AUTOSAR XML (schema 3.1.2)
package /Components/SWC_AdvSpT
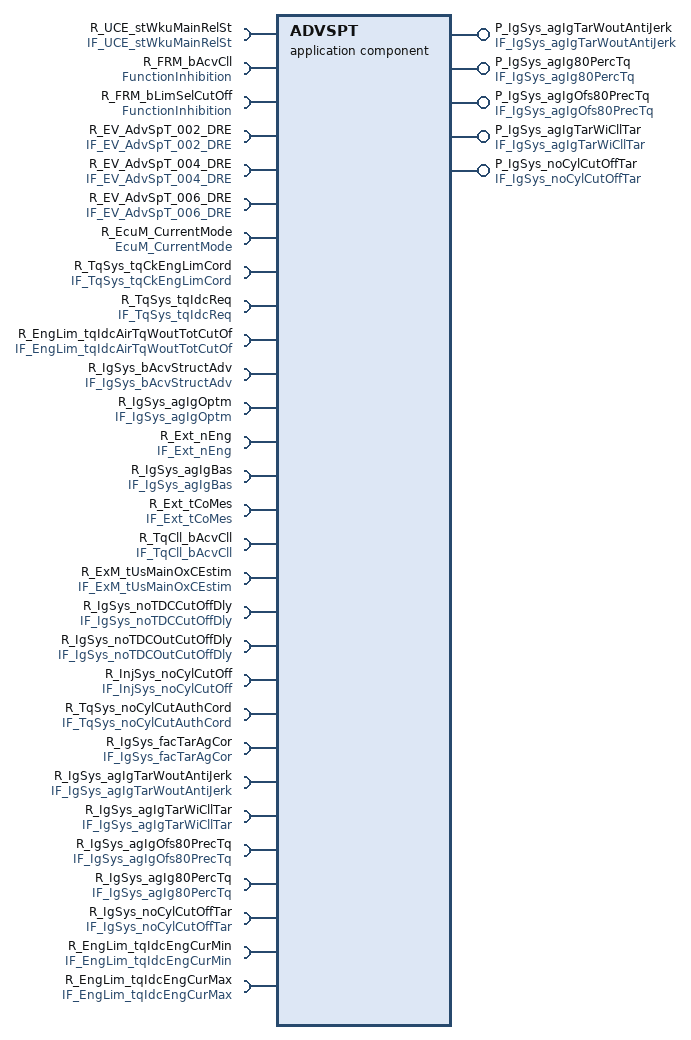
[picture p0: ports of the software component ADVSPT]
  application software component type ADVSPT  # AdvSpT
    require port R_UCE_stWkuMainRelSt: required-interface=IF_UCE_stWkuMainRelSt
    require port R_FRM_bAcvCll: required-interface=FunctionInhibition
    require port R_FRM_bLimSelCutOff: required-interface=FunctionInhibition
    5 x provide port:
      P_IgSys_agIgTarWoutAntiJerk: unqueued-sender-com-spec{data-element=IgSys_agIgTarWoutAntiJerk, can-invalidate=false, init-value=UInt8InitValue}, provided-interface=IF_IgSys_agIgTarWoutAntiJerk
      P_IgSys_agIg80PercTq: unqueued-sender-com-spec{data-element=IgSys_agIg80PercTq, can-invalidate=false, init-value=UInt8InitValue1}, provided-interface=IF_IgSys_agIg80PercTq
      P_IgSys_agIgOfs80PrecTq: unqueued-sender-com-spec{data-element=IgSys_agIgOfs80PrecTq, can-invalidate=false, init-value=UInt8InitValue3}, provided-interface=IF_IgSys_agIgOfs80PrecTq
      P_IgSys_agIgTarWiCllTar: unqueued-sender-com-spec{data-element=IgSys_agIgTarWiCllTar, can-invalidate=false, init-value=ConstantValue}, provided-interface=IF_IgSys_agIgTarWiCllTar
      P_IgSys_noCylCutOffTar: unqueued-sender-com-spec{data-element=IgSys_noCylCutOffTar, can-invalidate=false, init-value=UInt8InitValue5}, provided-interface=IF_IgSys_noCylCutOffTar
    26 x require port:
      R_EV_AdvSpT_002_DRE: unqueued-receiver-com-spec{data-element=EV_AdvSpT_002_DRE, init-value=UInt8InitValue7, resync-time=0}, required-interface=IF_EV_AdvSpT_002_DRE
      R_EV_AdvSpT_004_DRE: unqueued-receiver-com-spec{data-element=EV_AdvSpT_004_DRE, init-value=UInt8InitValue9, resync-time=0}, required-interface=IF_EV_AdvSpT_004_DRE
      R_EV_AdvSpT_006_DRE: unqueued-receiver-com-spec{data-element=EV_AdvSpT_006_DRE, init-value=UInt8InitValue11, resync-time=0}, required-interface=IF_EV_AdvSpT_006_DRE
      R_EcuM_CurrentMode: required-interface=EcuM_CurrentMode
      R_TqSys_tqCkEngLimCord: unqueued-receiver-com-spec{data-element=TqSys_tqCkEngLimCord, init-value=SInt16InitValue, resync-time=0}, required-interface=IF_TqSys_tqCkEngLimCord
      R_TqSys_tqIdcReq: unqueued-receiver-com-spec{data-element=TqSys_tqIdcReq, init-value=SInt16InitValue13, resync-time=0}, required-interface=IF_TqSys_tqIdcReq
      R_EngLim_tqIdcAirTqWoutTotCutOf: unqueued-receiver-com-spec{data-element=EngLim_tqIdcAirTqWoutTotCutOf, init-value=SInt16InitValue15, resync-time=0}, required-interface=IF_EngLim_tqIdcAirTqWoutTotCutOf
      R_IgSys_bAcvStructAdv: unqueued-receiver-com-spec{data-element=IgSys_bAcvStructAdv, init-value=ConstantValue17, resync-time=0}, required-interface=IF_IgSys_bAcvStructAdv
      R_IgSys_agIgOptm: unqueued-receiver-com-spec{data-element=IgSys_agIgOptm, init-value=ConstantValue19, resync-time=0}, required-interface=IF_IgSys_agIgOptm
      R_Ext_nEng: unqueued-receiver-com-spec{data-element=Ext_nEng, init-value=ConstantValue21, resync-time=0}, required-interface=IF_Ext_nEng
      R_IgSys_agIgBas: unqueued-receiver-com-spec{data-element=IgSys_agIgBas, init-value=ConstantValue23, resync-time=0}, required-interface=IF_IgSys_agIgBas
      R_Ext_tCoMes: unqueued-receiver-com-spec{data-element=Ext_tCoMes, init-value=ConstantValue25, resync-time=0}, required-interface=IF_Ext_tCoMes
      R_TqCll_bAcvCll: unqueued-receiver-com-spec{data-element=TqCll_bAcvCll, init-value=BooleanInitValue, resync-time=0}, required-interface=IF_TqCll_bAcvCll
      R_ExM_tUsMainOxCEstim: unqueued-receiver-com-spec{data-element=ExM_tUsMainOxCEstim, init-value=UInt16InitValue, resync-time=0}, required-interface=IF_ExM_tUsMainOxCEstim
      R_IgSys_noTDCCutOffDly: unqueued-receiver-com-spec{data-element=IgSys_noTDCCutOffDly, init-value=UInt8InitValue27, resync-time=0}, required-interface=IF_IgSys_noTDCCutOffDly
      R_IgSys_noTDCOutCutOffDly: unqueued-receiver-com-spec{data-element=IgSys_noTDCOutCutOffDly, init-value=UInt8InitValue29, resync-time=0}, required-interface=IF_IgSys_noTDCOutCutOffDly
      R_InjSys_noCylCutOff: unqueued-receiver-com-spec{data-element=InjSys_noCylCutOff, init-value=ConstantValue31, resync-time=0}, required-interface=IF_InjSys_noCylCutOff
      R_TqSys_noCylCutAuthCord: unqueued-receiver-com-spec{data-element=TqSys_noCylCutAuthCord, init-value=UInt8InitValue33, resync-time=0}, required-interface=IF_TqSys_noCylCutAuthCord
      R_IgSys_facTarAgCor: unqueued-receiver-com-spec{data-element=IgSys_facTarAgCor, init-value=UInt16InitValue35, resync-time=0}, required-interface=IF_IgSys_facTarAgCor
      R_IgSys_agIgTarWoutAntiJerk: unqueued-receiver-com-spec{data-element=IgSys_agIgTarWoutAntiJerk, init-value=UInt8InitValue, resync-time=0}, required-interface=IF_IgSys_agIgTarWoutAntiJerk
      R_IgSys_agIgTarWiCllTar: unqueued-receiver-com-spec{data-element=IgSys_agIgTarWiCllTar, init-value=ConstantValue, resync-time=0}, required-interface=IF_IgSys_agIgTarWiCllTar
      R_IgSys_agIgOfs80PrecTq: unqueued-receiver-com-spec{data-element=IgSys_agIgOfs80PrecTq, init-value=UInt8InitValue37, resync-time=0}, required-interface=IF_IgSys_agIgOfs80PrecTq
      R_IgSys_agIg80PercTq: unqueued-receiver-com-spec{data-element=IgSys_agIg80PercTq, init-value=UInt8InitValue39, resync-time=0}, required-interface=IF_IgSys_agIg80PercTq
      R_IgSys_noCylCutOffTar: unqueued-receiver-com-spec{data-element=IgSys_noCylCutOffTar, init-value=UInt8InitValue41, resync-time=0}, required-interface=IF_IgSys_noCylCutOffTar
      R_EngLim_tqIdcEngCurMin: unqueued-receiver-com-spec{data-element=EngLim_tqIdcEngCurMin, init-value=SInt16InitValue43, resync-time=0}, required-interface=IF_EngLim_tqIdcEngCurMin
      R_EngLim_tqIdcEngCurMax: unqueued-receiver-com-spec{data-element=EngLim_tqIdcEngCurMax, init-value=SInt16InitValue45, resync-time=0}, required-interface=IF_EngLim_tqIdcEngCurMax
  30 x constant specification:
    BooleanInitValue
      value:
        boolean literal BooleanInitValue: type=DT_TqCll_bAcvCll, value=false
    ConstantValue
      value:
        integer literal ConstantValue: type=DT_IgSys_agIgTarWiCllTar, value=150
    ConstantValue17
      value:
        boolean literal ConstantValue17: type=DT_IgSys_bAcvStructAdv, value=false
    ConstantValue19
      value:
        integer literal ConstantValue19: type=DT_IgSys_agIgOptm, value=149
    ConstantValue21
      value:
        integer literal ConstantValue21: type=DT_Ext_nEng, value=0
    ConstantValue23
      value:
        integer literal ConstantValue23: type=DT_IgSys_agIgBas, value=149
    ConstantValue25
      value:
        integer literal ConstantValue25: type=DT_Ext_tCoMes, value=20
    ConstantValue31
      value:
        integer literal ConstantValue31: type=DT_InjSys_noCylCutOff, value=0
    InitValue_UInt16_0
      value:
        integer literal InitValue_UInt16_0: type=DT_IgSys_rTarEfcWoutAntiJerk_irv, value=0
    InitValue_UInt16_047
      value:
        integer literal InitValue_UInt16_047: type=DT_IgSys_rTarEfc_irv, value=0
    SInt16InitValue
      value:
        integer literal SInt16InitValue: type=DT_TqSys_tqCkEngLimCord, value=0
    SInt16InitValue13
      value:
        integer literal SInt16InitValue13: type=DT_TqSys_tqIdcReq, value=0
    SInt16InitValue15
      value:
        integer literal SInt16InitValue15: type=DT_EngLim_tqIdcAirTqWoutTotCutOf, value=0
    SInt16InitValue43
      value:
        integer literal SInt16InitValue43: type=DT_EngLim_tqIdcEngCurMin, value=0
    SInt16InitValue45
      value:
        integer literal SInt16InitValue45: type=DT_EngLim_tqIdcEngCurMax, value=32000
    UInt16InitValue
      value:
        integer literal UInt16InitValue: type=DT_ExM_tUsMainOxCEstim, value=0
    UInt16InitValue35
      value:
        integer literal UInt16InitValue35: type=DT_IgSys_facTarAgCor, value=256
    UInt8InitValue
      value:
        integer literal UInt8InitValue: type=DT_IgSys_agIgTarWoutAntiJerk, value=150
    UInt8InitValue1
      value:
        integer literal UInt8InitValue1: type=DT_IgSys_agIg80PercTq, value=96
    UInt8InitValue11
      value:
        integer literal UInt8InitValue11: type=DT_EV_AdvSpT_006_DRE, value=0
    UInt8InitValue27
      value:
        integer literal UInt8InitValue27: type=DT_IgSys_noTDCCutOffDly, value=0
    UInt8InitValue29
      value:
        integer literal UInt8InitValue29: type=DT_IgSys_noTDCOutCutOffDly, value=0
    UInt8InitValue3
      value:
        integer literal UInt8InitValue3: type=DT_IgSys_agIgOfs80PrecTq, value=96
    UInt8InitValue33
      value:
        integer literal UInt8InitValue33: type=DT_TqSys_noCylCutAuthCord, value=0
    UInt8InitValue37
      value:
        integer literal UInt8InitValue37: type=DT_IgSys_agIgOfs80PrecTq, value=96
    UInt8InitValue39
      value:
        integer literal UInt8InitValue39: type=DT_IgSys_agIg80PercTq, value=96
    UInt8InitValue41
      value:
        integer literal UInt8InitValue41: type=DT_IgSys_noCylCutOffTar, value=0
    UInt8InitValue5
      value:
        integer literal UInt8InitValue5: type=DT_IgSys_noCylCutOffTar, value=0
    UInt8InitValue7
      value:
        integer literal UInt8InitValue7: type=DT_EV_AdvSpT_002_DRE, value=0
    UInt8InitValue9
      value:
        integer literal UInt8InitValue9: type=DT_EV_AdvSpT_004_DRE, value=0
  internal behavior IB_AdvSpT: component=ADVSPT
    data received event EV_AdvSpT_004_DRE: mode-dependency=dependent-on-mode=[R_UCE_stWkuMainRelSt.RCD_stWkuMainRelSt.PreMainWakeUp, R_UCE_stWkuMainRelSt.RCD_stWkuMainRelSt.PostMainWakeUp, R_UCE_stWkuMainRelSt.RCD_stWkuMainRelSt.Invalid], start-on-event=RE_AdvSpT_004_DRE, data=R_EV_AdvSpT_004_DRE.EV_AdvSpT_004_DRE
    data received event EV_AdvSpT_006_DRE: mode-dependency=dependent-on-mode=[R_UCE_stWkuMainRelSt.RCD_stWkuMainRelSt.PreMainWakeUp, R_UCE_stWkuMainRelSt.RCD_stWkuMainRelSt.PostMainWakeUp, R_UCE_stWkuMainRelSt.RCD_stWkuMainRelSt.Invalid], start-on-event=RE_AdvSpT_006_DRE, data=R_EV_AdvSpT_006_DRE.EV_AdvSpT_006_DRE
    mode switch event EV_AdvSpT_005_MSE: start-on-event=RE_AdvSpT_005_MSE, activation=ENTRY, mode=R_EcuM_CurrentMode.currentMode.RUN
    mode switch event EV_AdvSpT_003_MSE: start-on-event=RE_AdvSpT_003_MSE, activation=ENTRY, mode=R_EcuM_CurrentMode.currentMode.RUN
    mode switch event EV_AdvSpT_001_MSE: start-on-event=RE_AdvSpT_001_MSE, activation=ENTRY, mode=R_EcuM_CurrentMode.currentMode.RUN
    data received event EV_AdvSpT_002_DRE: mode-dependency=dependent-on-mode=[R_UCE_stWkuMainRelSt.RCD_stWkuMainRelSt.PreMainWakeUp, R_UCE_stWkuMainRelSt.RCD_stWkuMainRelSt.PostMainWakeUp, R_UCE_stWkuMainRelSt.RCD_stWkuMainRelSt.Invalid], start-on-event=RE_AdvSpT_002_DRE, data=R_EV_AdvSpT_002_DRE.EV_AdvSpT_002_DRE
    inter runnable variable IgSys_rTarEfc_irv: sw-calibration-access=READ-WRITE, type=DT_IgSys_rTarEfc_irv, communication-approach=EXPLICIT, init-value=InitValue_UInt16_047
    inter runnable variable IgSys_rTarEfcWoutAntiJerk_irv: sw-calibration-access=READ-WRITE, type=DT_IgSys_rTarEfcWoutAntiJerk_irv, communication-approach=EXPLICIT, init-value=InitValue_UInt16_0
    6 x runnable:
      RE_AdvSpT_001_MSE: written-variable=[IgSys_rTarEfc_irv, IgSys_rTarEfcWoutAntiJerk_irv]
      RE_AdvSpT_002_DRE: read-variable=[IgSys_rTarEfc_irv, IgSys_rTarEfcWoutAntiJerk_irv], written-variable=[IgSys_rTarEfc_irv, IgSys_rTarEfcWoutAntiJerk_irv]
        5 x data receive point:
          dr_EV_AdvSpT_002_DRE: data-element=R_EV_AdvSpT_002_DRE.EV_AdvSpT_002_DRE
          dr_IgSys_bAcvStructAdv: data-element=R_IgSys_bAcvStructAdv.IgSys_bAcvStructAdv
          dr_TqSys_tqCkEngLimCord: data-element=R_TqSys_tqCkEngLimCord.TqSys_tqCkEngLimCord
          dr_TqSys_tqIdcReq: data-element=R_TqSys_tqIdcReq.TqSys_tqIdcReq
          dr_EngLim_tqIdcAirTqWoutTotCutOf: data-element=R_EngLim_tqIdcAirTqWoutTotCutOf.EngLim_tqIdcAirTqWoutTotCutOf
      RE_AdvSpT_003_MSE
        data send point ds_IgSys_noCylCutOffTar: data-element=P_IgSys_noCylCutOffTar.IgSys_noCylCutOffTar
      RE_AdvSpT_006_DRE: read-variable=[IgSys_rTarEfcWoutAntiJerk_irv, IgSys_rTarEfc_irv]
        10 x data receive point:
          dr_IgSys_bAcvStructAdv: data-element=R_IgSys_bAcvStructAdv.IgSys_bAcvStructAdv
          dr_IgSys_agIg80PercTq: data-element=R_IgSys_agIg80PercTq.IgSys_agIg80PercTq
          dr_IgSys_agIgBas: data-element=R_IgSys_agIgBas.IgSys_agIgBas
          dr_IgSys_agIgOptm: data-element=R_IgSys_agIgOptm.IgSys_agIgOptm
          dr_TqCll_bAcvCll: data-element=R_TqCll_bAcvCll.TqCll_bAcvCll
          dr_IgSys_agIgOfs80PrecTq: data-element=R_IgSys_agIgOfs80PrecTq.IgSys_agIgOfs80PrecTq
          dr_IgSys_facTarAgCor: data-element=R_IgSys_facTarAgCor.IgSys_facTarAgCor
          dr_EV_AdvSpT_006_DRE: data-element=R_EV_AdvSpT_006_DRE.EV_AdvSpT_006_DRE
          dr_IgSys_agIgTarWoutAntiJerk: data-element=R_IgSys_agIgTarWoutAntiJerk.IgSys_agIgTarWoutAntiJerk
          dr_IgSys_agIgTarWiCllTar: data-element=R_IgSys_agIgTarWiCllTar.IgSys_agIgTarWiCllTar
        data send point ds_IgSys_agIgTarWoutAntiJerk: data-element=P_IgSys_agIgTarWoutAntiJerk.IgSys_agIgTarWoutAntiJerk
        data send point ds_IgSys_agIgOfs80PrecTq: data-element=P_IgSys_agIgOfs80PrecTq.IgSys_agIgOfs80PrecTq
        data send point ds_IgSys_agIg80PercTq: data-element=P_IgSys_agIg80PercTq.IgSys_agIg80PercTq
        sync call ssp_FRM_bAcvCll: operation=R_FRM_bAcvCll.GetFunctionPermission
      RE_AdvSpT_005_MSE
        4 x data send point:
          ds_IgSys_agIgTarWiCllTar: data-element=P_IgSys_agIgTarWiCllTar.IgSys_agIgTarWiCllTar
          ds_IgSys_agIgTarWoutAntiJerk: data-element=P_IgSys_agIgTarWoutAntiJerk.IgSys_agIgTarWoutAntiJerk
          ds_IgSys_agIg80PercTq: data-element=P_IgSys_agIg80PercTq.IgSys_agIg80PercTq
          ds_IgSys_agIgOfs80PrecTq: data-element=P_IgSys_agIgOfs80PrecTq.IgSys_agIgOfs80PrecTq
      RE_AdvSpT_004_DRE
        13 x data receive point:
          dr_IgSys_noCylCutOffTar: data-element=R_IgSys_noCylCutOffTar.IgSys_noCylCutOffTar
          dr_EngLim_tqIdcEngCurMin: data-element=R_EngLim_tqIdcEngCurMin.EngLim_tqIdcEngCurMin
          dr_EngLim_tqIdcEngCurMax: data-element=R_EngLim_tqIdcEngCurMax.EngLim_tqIdcEngCurMax
          dr_IgSys_noTDCOutCutOffDly: data-element=R_IgSys_noTDCOutCutOffDly.IgSys_noTDCOutCutOffDly
          dr_Ext_nEng: data-element=R_Ext_nEng.Ext_nEng
          dr_TqSys_tqIdcReq: data-element=R_TqSys_tqIdcReq.TqSys_tqIdcReq
          dr_ExM_tUsMainOxCEstim: data-element=R_ExM_tUsMainOxCEstim.ExM_tUsMainOxCEstim
          dr_EV_AdvSpT_004_DRE: data-element=R_EV_AdvSpT_004_DRE.EV_AdvSpT_004_DRE
          dr_TqSys_noCylCutAuthCord: data-element=R_TqSys_noCylCutAuthCord.TqSys_noCylCutAuthCord
          dr_InjSys_noCylCutOff: data-element=R_InjSys_noCylCutOff.InjSys_noCylCutOff
          dr_IgSys_noTDCCutOffDly: data-element=R_IgSys_noTDCCutOffDly.IgSys_noTDCCutOffDly
          dr_IgSys_bAcvStructAdv: data-element=R_IgSys_bAcvStructAdv.IgSys_bAcvStructAdv
          dr_Ext_tCoMes: data-element=R_Ext_tCoMes.Ext_tCoMes
        data send point ds_IgSys_noCylCutOffTar: data-element=P_IgSys_noCylCutOffTar.IgSys_noCylCutOffTar
        sync call ssp_FRM_bLimSelCutOff: operation=R_FRM_bLimSelCutOff.GetFunctionPermission
  swc implementation Imp_AdvSpT: code-generator=Real-Time Workshop Embedded Coder 5.5 (R2010a) 25-Jan-2010, programming-language=C, behavior=IB_AdvSpT
    code-descriptors:
      code CodeDescriptor: type=SRC
        9 x xfile:
          AdvSpT_import_h: url=AdvSpT_import.h
          AdvSpT_Version_c: url=AdvSpT_Version.c
          AdvSpT_private_h: url=AdvSpT_private.h
          AdvSpT_h: url=AdvSpT.h
          AdvSpT_Def_c: url=AdvSpT_Def.c
          AdvSpT_MemMap_h: url=AdvSpT_MemMap.h
          AdvSpT_c: url=AdvSpT.c
          AdvSpT_types_h: url=AdvSpT_types.h
          AdvSpT_Version_h: url=AdvSpT_Version.h
package /Components/SWC_AdvSpT/AdvSpT_IRVDatatypes
  integer type DT_IgSys_rTarEfc_irv: base-type=uint16, lower-limit=0, upper-limit=65535
  integer type DT_IgSys_rTarEfcWoutAntiJerk_irv: base-type=uint16, lower-limit=0, upper-limit=65535
